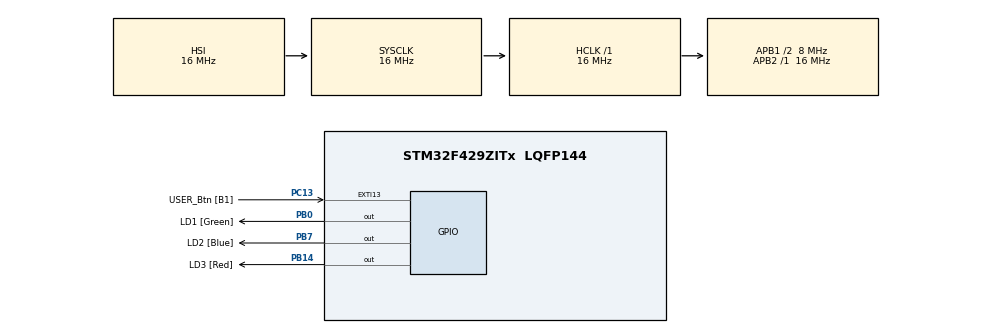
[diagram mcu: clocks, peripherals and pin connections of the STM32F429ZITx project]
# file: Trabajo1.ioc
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Mcu.Family=STM32F4
Mcu.Name=STM32F429ZITx
Mcu.Package=LQFP144
NVIC.PriorityGroup=NVIC_PRIORITYGROUP_4
PA13.GPIO_Label=TMS
PA13.Mode=Serial_Wire
PA13.Signal=SYS_JTMS-SWDIO
PA14.GPIO_Label=TCK
PA14.Mode=Serial_Wire
PA14.Signal=SYS_JTCK-SWCLK
PB0.GPIO_Label=LD1 [Green]
PB0.Signal=GPIO_Output
PB14.GPIO_Label=LD3 [Red]
PB14.Signal=GPIO_Output
PB7.GPIO_Label=LD2 [Blue]
PB7.Signal=GPIO_Output
PC13.GPIO_Label=USER_Btn [B1]
PC13.Signal=GPXTI13
PC14/OSC32_IN.Mode=LSE-External-Oscillator
PC14/OSC32_IN.Signal=RCC_OSC32_IN
PC15/OSC32_OUT.Mode=LSE-External-Oscillator
PC15/OSC32_OUT.Signal=RCC_OSC32_OUT
PD8.Signal=USART3_TX
PD9.Signal=USART3_RX
PH0/OSC_IN.GPIO_Label=MCO [STM32F103CBT6_PA8]
PH0/OSC_IN.Mode=HSE-External-Oscillator
PH0/OSC_IN.Signal=RCC_OSC_IN
PH1/OSC_OUT.Mode=HSE-External-Oscillator
PH1/OSC_OUT.Signal=RCC_OSC_OUT
ProjectManager.HeapSize=0x200
ProjectManager.StackSize=0x400
ProjectManager.TargetToolchain=STM32CubeIDE
RCC.48MHZClocksFreq_Value=48000000
RCC.AHBFreq_Value=16000000
RCC.APB1CLKDivider=RCC_HCLK_DIV2
RCC.APB1Freq_Value=8000000
RCC.APB1TimFreq_Value=16000000
RCC.APB2Freq_Value=16000000
RCC.APB2TimFreq_Value=16000000
RCC.CortexFreq_Value=16000000
RCC.HCLKFreq_Value=16000000
RCC.HSE_VALUE=8000000
RCC.HSI_VALUE=16000000
RCC.PLLMUL=RCC_PLL_MUL9
RCC.PRESCALERUSB=RCC_USBCLKSOURCE_PLL_DIV1_5
RCC.SYSCLKFreq_VALUE=16000000
RCC.SYSCLKSourceVirtual=RCC_SYSCLKSOURCE_PLLCLK
RCC.USBFreq_Value=48000000
RCC.VCOOutputFreq_Value=192000000
board=NUCLEO-F429ZI

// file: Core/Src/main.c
/* USER CODE BEGIN Header */
/**
  ******************************************************************************
  * @file           : main.c
  * @brief          : Main program body
  ******************************************************************************
  * @attention
  *
  * Copyright (c) 2023 STMicroelectronics.
  * All rights reserved.
  *
  * This software is licensed under terms that can be found in the LICENSE file
  * in the root directory of this software component.
  * If no LICENSE file comes with this software, it is provided AS-IS.
  *
  ******************************************************************************
  */
/* USER CODE END Header */
#include "main.h"

/* USER CODE BEGIN PD */
#define	Delay_Led				50  //frecuencia base para leds

/* USER CODE END PD */

void SystemClock_Config(void);

int main(void)
{

  /* MCU Configuration--------------------------------------------------------*/

  /* Reset of all peripherals, Initializes the Flash interface and the Systick. */
  HAL_Init();

  /* USER CODE BEGIN Init */
  BSP_LED_Init(LED1);  // inicializa los puestos fisicos cableados de la board
  BSP_LED_Init(LED2);  // BSP -> Board Support Package
  BSP_LED_Init(LED3);

  /* USER CODE END Init */

  /* Configure the system clock */
  SystemClock_Config();

  /* Initialize all configured peripherals */

  /* Infinite loop */
  while (1)
  {
	  BSP_LED_Toggle(LED1);
	  HAL_Delay(Delay_Led);
	  BSP_LED_Toggle(LED1);
	  HAL_Delay(Delay_Led);
	  BSP_LED_Toggle(LED2);
	  HAL_Delay(Delay_Led);
	  BSP_LED_Toggle(LED2);
	  HAL_Delay(Delay_Led);
	  BSP_LED_Toggle(LED3);
	  HAL_Delay(Delay_Led);
	  BSP_LED_Toggle(LED3);
	  HAL_Delay(Delay_Led);
  }
}

void SystemClock_Config(void)
{
  RCC_OscInitTypeDef RCC_OscInitStruct = {0};
  RCC_ClkInitTypeDef RCC_ClkInitStruct = {0};

  /** Configure the main internal regulator output voltage
  */
  __HAL_RCC_PWR_CLK_ENABLE();
  __HAL_PWR_VOLTAGESCALING_CONFIG(PWR_REGULATOR_VOLTAGE_SCALE3);

  /** Initializes the RCC Oscillators according to the specified parameters
  * in the RCC_OscInitTypeDef structure.
  */
  RCC_OscInitStruct.OscillatorType = RCC_OSCILLATORTYPE_HSI;
  RCC_OscInitStruct.HSIState = RCC_HSI_ON;
  RCC_OscInitStruct.HSICalibrationValue = RCC_HSICALIBRATION_DEFAULT;
  RCC_OscInitStruct.PLL.PLLState = RCC_PLL_NONE;
  if (HAL_RCC_OscConfig(&RCC_OscInitStruct) != HAL_OK)
  {
    Error_Handler();
  }

  /** Initializes the CPU, AHB and APB buses clocks
  */
  RCC_ClkInitStruct.ClockType = RCC_CLOCKTYPE_HCLK|RCC_CLOCKTYPE_SYSCLK
                              |RCC_CLOCKTYPE_PCLK1|RCC_CLOCKTYPE_PCLK2;
  RCC_ClkInitStruct.SYSCLKSource = RCC_SYSCLKSOURCE_HSI;
  RCC_ClkInitStruct.AHBCLKDivider = RCC_SYSCLK_DIV1;
  RCC_ClkInitStruct.APB1CLKDivider = RCC_HCLK_DIV2;
  RCC_ClkInitStruct.APB2CLKDivider = RCC_HCLK_DIV1;

  if (HAL_RCC_ClockConfig(&RCC_ClkInitStruct, FLASH_LATENCY_0) != HAL_OK)
  {
    Error_Handler();
  }
}

void Error_Handler(void)
{
  __disable_irq();
  while (1)
  {
  }
}
